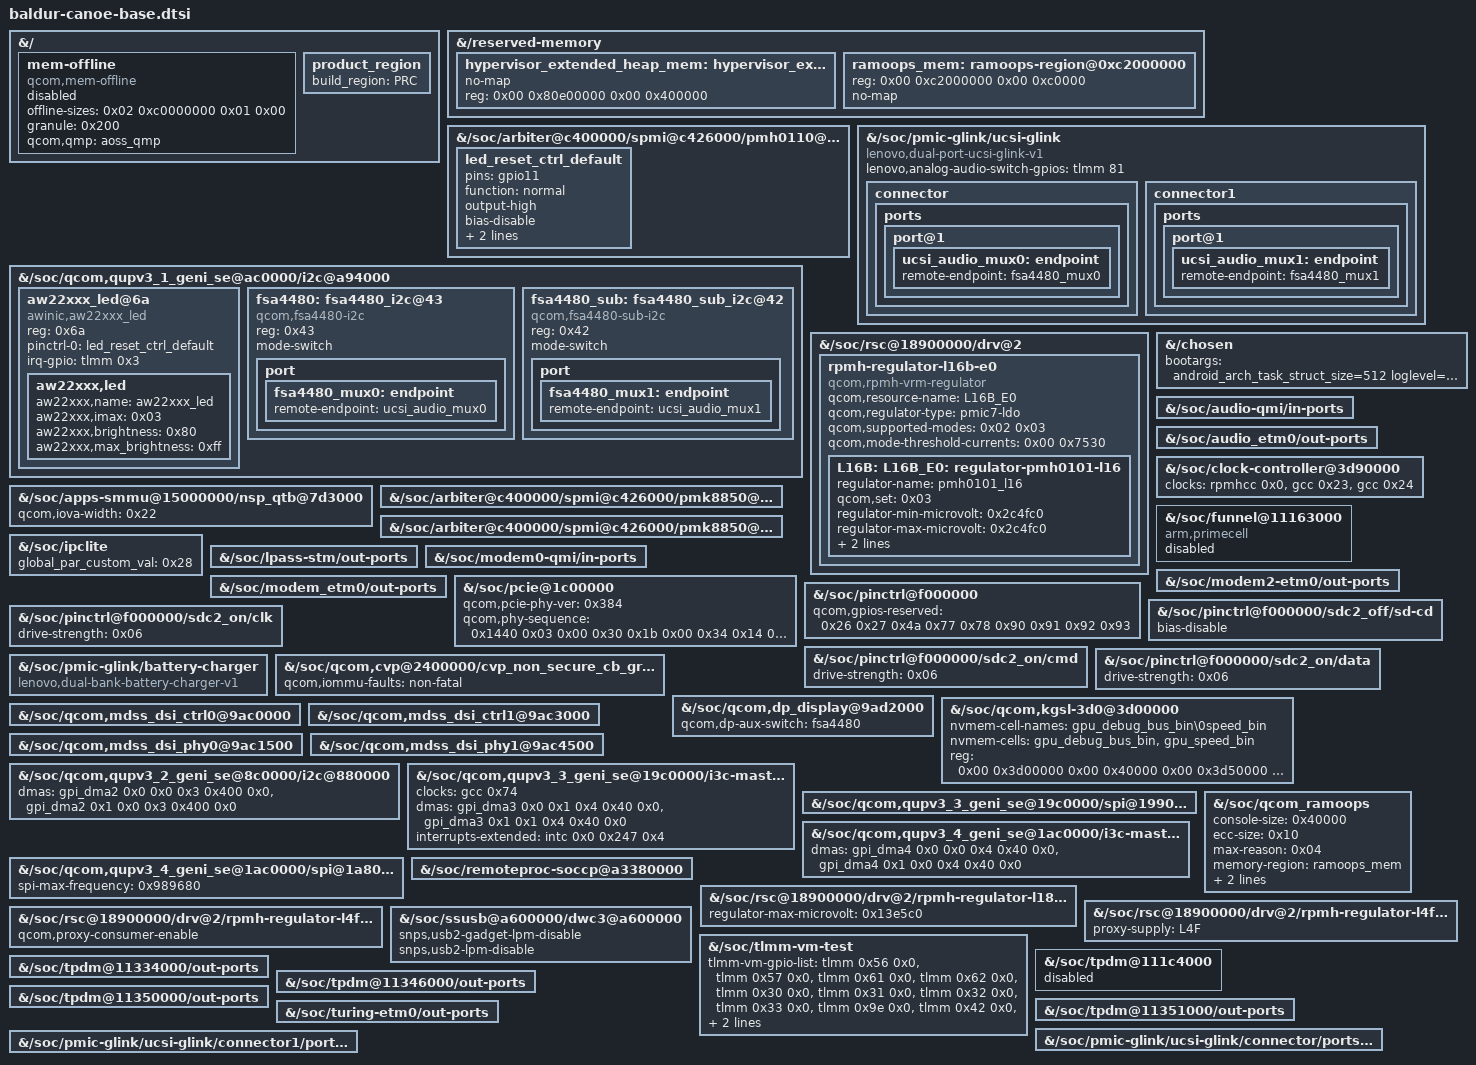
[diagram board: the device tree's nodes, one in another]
// SPDX-License-Identifier: GPL-2.0-only
// ZUXOS 2.0.12.088 PRC base entry 12 delta over the QTI CanoeP v2 techpack set.

/delete-node/ &{/ddr-regions};
/delete-node/ &{/reserved-memory/hypervisor_extended_heap_region@0xc3dd0000};
/delete-node/ &{/reserved-memory/ramoops-region};
/delete-node/ &{/reserved-memory/reserved_region@80e00000};
/delete-node/ &{/soc/arbiter@c400000/spmi@c426000/pmh0110@8/pinctrl@8800/cam-sensor-1p8-rst1-active-state};
/delete-node/ &{/soc/arbiter@c400000/spmi@c426000/pmh0110@8/pinctrl@8800/cam-sensor-1p8-rst1-suspend-state};
/delete-node/ &{/soc/arbiter@c400000/spmi@c426000/pmk8850@0/pinctrl@b800/alt-sleep-clk-default-state};
/delete-node/ &{/soc/arbiter@c400000/spmi@c426000/pmk8850@0/pinctrl@b800/xoagg-therm-default-state};
/delete-node/ &{/soc/arbiter@c400000/spmi@c426000/pmk8850@0/vadc@9000/pmh0101_cam_flash_therm};
/delete-node/ &{/soc/arbiter@c400000/spmi@c426000/pmk8850@0/vadc@9000/pmh0101_pa_therm1};
/delete-node/ &{/soc/arbiter@c400000/spmi@c426000/pmk8850@0/vadc@9000/pmh0101_pa_therm2};
/delete-node/ &{/soc/arbiter@c400000/spmi@c426000/pmk8850@0/vadc@9000/pmh0101_skin_therm};
/delete-node/ &{/soc/arbiter@c400000/spmi@c426000/pmk8850@0/vadc@9000/pmh0101_wlan_therm};
/delete-node/ &{/soc/arbiter@c400000/spmi@c426000/pmk8850@0/vadc@9000/pmk8850_xoagg_therm};
/delete-node/ &{/soc/funnel@11163000/in-ports};
/delete-node/ &{/soc/qcom,gpu-coresight-cx};
/delete-node/ &{/soc/qcom,gpu-coresight-gx};
/delete-node/ &{/soc/qcom,mdss_dsi_ctrl0@9ac0000/qcom,ctrl-supply-entries/qcom,ctrl-supply-entry@1};
/delete-node/ &{/soc/qcom,mdss_dsi_ctrl1@9ac3000/qcom,ctrl-supply-entries/qcom,ctrl-supply-entry@1};
/delete-node/ &{/soc/qcom,mdss_dsi_phy0@9ac1500/qcom,phy-supply-entries/qcom,phy-supply-entry@1};
/delete-node/ &{/soc/qcom,mdss_dsi_phy1@9ac4500/qcom,phy-supply-entries/qcom,phy-supply-entry@1};
/delete-node/ &{/soc/qfprom@221c8000/debugbus_en@783};
/delete-node/ &{/soc/qfprom@221c8000/gpu_niden_en@783};
/delete-node/ &{/soc/qmi-tmd-devices/modem/modem_bcl_mtpl_dsc};

&{/} {
	mem-offline {
		compatible = "qcom,mem-offline";
		status = "disabled";
		offline-sizes = <0x02 0xc0000000 0x01 0x00>;
		granule = <0x200>;
		qcom,qmp = <&aoss_qmp>;
	};
};

&{/} {
	product_region: product_region {
		build_region = "PRC";
	};
};

&{/reserved-memory} {
	hypervisor_extended_heap_mem: hypervisor_extended_heap_region@80e00000 {
		no-map;
		reg = <0x00 0x80e00000 0x00 0x400000>;
	};
};

&{/reserved-memory} {
	ramoops_mem: ramoops-region@0xc2000000 {
		reg = <0x00 0xc2000000 0x00 0xc0000>;
		no-map;
	};
};

&{/soc/arbiter@c400000/spmi@c426000/pmh0110@3/pinctrl@8800} {
	led_reset_ctrl_default: led_reset_ctrl_default {
		pins = "gpio11";
		function = "normal";
		output-high;
		bias-disable;
		power-source = <0x01>;
		qcom,drive-strength = <0x02>;
	};
};

&{/soc/pmic-glink/ucsi-glink} {
	compatible = "lenovo,dual-port-ucsi-glink-v1", "qcom,ucsi-glink";
	lenovo,analog-audio-switch-gpios = <&tlmm 81 GPIO_ACTIVE_HIGH>;
	connector {
		ports {
			port@1 {
				ucsi_audio_mux0: endpoint {
					remote-endpoint = <&fsa4480_mux0>;
				};
			};
		};
	};
};

&{/soc/pmic-glink/ucsi-glink} {
	connector1 {
		ports {
			port@1 {
				ucsi_audio_mux1: endpoint {
					remote-endpoint = <&fsa4480_mux1>;
				};
			};
		};
	};
};

&{/soc/qcom,qupv3_1_geni_se@ac0000/i2c@a94000} {
	aw22xxx_led@6a {
		compatible = "awinic,aw22xxx_led";
		reg = <0x6a>;
		pinctrl-names = "led_reset_ctrl_default";
		pinctrl-0 = <&led_reset_ctrl_default>;
		irq-gpio = <&tlmm 0x3 0x0>;
		status = "okay";
		aw22xxx,led {
			aw22xxx,name = "aw22xxx_led";
			aw22xxx,imax = <0x03>;
			aw22xxx,brightness = <0x80>;
			aw22xxx,max_brightness = <0xff>;
		};
	};
};

&{/soc/qcom,qupv3_1_geni_se@ac0000/i2c@a94000} {
	fsa4480: fsa4480_i2c@43 {
		compatible = "qcom,fsa4480-i2c";
		reg = <0x43>;
		mode-switch;
		port {
			fsa4480_mux0: endpoint {
				remote-endpoint = <&ucsi_audio_mux0>;
			};
		};
	};
};

&{/soc/qcom,qupv3_1_geni_se@ac0000/i2c@a94000} {
	fsa4480_sub: fsa4480_sub_i2c@42 {
		compatible = "qcom,fsa4480-sub-i2c";
		reg = <0x42>;
		mode-switch;
		port {
			fsa4480_mux1: endpoint {
				remote-endpoint = <&ucsi_audio_mux1>;
			};
		};
	};
};

&{/soc/rsc@18900000/drv@2} {
	rpmh-regulator-l16b-e0 {
		compatible = "qcom,rpmh-vrm-regulator";
		qcom,resource-name = "L16B_E0";
		qcom,regulator-type = "pmic7-ldo";
		qcom,supported-modes = <0x02 0x03>;
		qcom,mode-threshold-currents = <0x00 0x7530>;
		L16B: L16B_E0: pmh0101_l16: regulator-pmh0101-l16 {
			regulator-name = "pmh0101_l16";
			qcom,set = <0x03>;
			regulator-min-microvolt = <0x2c4fc0>;
			regulator-max-microvolt = <0x2c4fc0>;
			qcom,init-voltage = <0x2c4fc0>;
			qcom,init-mode = <0x03>;
		};
	};
};

&{/chosen} {
	bootargs = "android_arch_task_struct_size=512 loglevel=6 log_buf_len=512K cpufreq.default_governor=performance sysctl.kernel.sched_pelt_multiplier=4 no-steal-acc kpti=0 swiotlb=0 loop.max_part=7 irqaffinity=0-1 fw_devlink.strict=1 pcie_ports=compat pci-msm-drv.pcie_sm_regs=0x1D07000,0x1040,0x1048,0x3000,0x1 kasan=off rcupdate.rcu_expedited=1 rcu_nocbs=0-7 cgroup_disable=pressure printk.console_no_auto_verbose=1 sysctl.kernel.panic_on_rcu_stall=1 ftrace_dump_on_oops disable_dma32=on restrict_cma_redirect=false";
};

&{/soc/apps-smmu@15000000/nsp_qtb@7d3000} {
	qcom,iova-width = <0x22>;
};

&{/soc/arbiter@c400000/spmi@c426000/pmk8850@0/pinctrl@b800} {
	/delete-property/ pinctrl-0;
	/delete-property/ pinctrl-names;
};

&{/soc/arbiter@c400000/spmi@c426000/pmk8850@0/vadc@9000/pmh0101_qtm_therm} {
	/delete-property/ status;
};

&{/soc/audio-qmi/in-ports} {
	/delete-property/ #address-cells;
	/delete-property/ #size-cells;
};

&{/soc/audio_etm0/out-ports} {
	/delete-property/ #address-cells;
	/delete-property/ #size-cells;
};

&{/soc/clock-controller@3d90000} {
	clock-names = "bi_tcxo\0gpll0_out_main\0gpll0_out_main_div";
	clocks = <&rpmhcc 0x0 &gcc 0x23 &gcc 0x24>;
};

&{/soc/funnel@11163000} {
	compatible = "arm,primecell";
	status = "disabled";
};

&{/soc/ipclite} {
	global_par_custom_val = <0x28>;
};

&{/soc/lpass-stm/out-ports} {
	/delete-property/ #address-cells;
	/delete-property/ #size-cells;
};

&{/soc/modem0-qmi/in-ports} {
	/delete-property/ #address-cells;
	/delete-property/ #size-cells;
};

&{/soc/modem2-etm0/out-ports} {
	/delete-property/ #address-cells;
	/delete-property/ #size-cells;
};

&{/soc/modem_etm0/out-ports} {
	/delete-property/ #address-cells;
	/delete-property/ #size-cells;
};

&{/soc/pcie@1c00000} {
	qcom,pcie-phy-ver = <0x384>;
	qcom,phy-sequence = <0x1440 0x03 0x00 0x30 0x1b 0x00 0x34 0x14 0x00 0x7c 0x00 0x00 0x80 0x40 0x00 0x84 0x00 0x00 0xb4 0x04 0x00 0xe0 0x05 0x00 0xe4 0x00 0x00 0xf4 0x07 0x00 0xf8 0x1f 0x00 0x58 0x90 0x00 0x118 0x02 0x00 0x11c 0x0d 0x00 0x148 0x53 0x00 0x14c 0x54 0x00 0x2dc 0x0b 0x00 0x2ec 0x04 0x00 0x2f0 0x05 0x00 0x2f4 0x15 0x00 0x370 0x00 0x00 0x378 0x89 0x00 0x3b4 0x2d 0x00 0x128 0x20 0x00 0x3d8 0x1c 0x00 0x3e0 0x04 0x00 0x2b8 0x01 0x00 0x2bc 0x05 0x00 0x2c4 0x00 0x00 0x2c8 0x00 0x00 0x2b4 0x00 0x00 0x258 0x40 0x00 0x25c 0x42 0x00 0x284 0x18 0x00 0x298 0x12 0x00 0x2ac 0x18 0x00 0x418 0xc2 0x00 0x41c 0xc2 0x00 0x420 0x18 0x00 0x428 0x0f 0x00 0x434 0x62 0x00 0x460 0xe4 0x00 0x464 0x63 0x00 0x468 0xd8 0x00 0x46c 0x99 0x00 0x470 0x67 0x00 0x484 0xa4 0x00 0x488 0xa4 0x00 0x48c 0x28 0x00 0x490 0x9f 0x00 0x494 0x48 0x00 0x498 0x24 0x00 0x51c 0x01 0x00 0x520 0x00 0x00 0x31c 0xff 0x00 0x320 0xff 0x00 0x308 0x30 0x00 0x30c 0x03 0x00 0x398 0x1f 0x00 0x39c 0x1f 0x00 0x3a0 0x0d 0x00 0x830 0x1b 0x00 0x834 0x14 0x00 0x87c 0x00 0x00 0x880 0x40 0x00 0x884 0x00 0x00 0x8b4 0x04 0x00 0x8e0 0x05 0x00 0x8e4 0x00 0x00 0x8f4 0x07 0x00 0x8f8 0x1f 0x00 0x858 0x90 0x00 0x918 0x02 0x00 0x91c 0x0d 0x00 0x948 0x53 0x00 0x94c 0x54 0x00 0xadc 0x0b 0x00 0xaec 0x04 0x00 0xaf0 0x05 0x00 0xaf4 0x15 0x00 0xb70 0x00 0x00 0xb78 0x89 0x00 0xbb4 0x2d 0x00 0x928 0x20 0x00 0xbd8 0x1c 0x00 0xbe0 0x04 0x00 0xab8 0x01 0x00 0xabc 0x05 0x00 0xac4 0x00 0x00 0xac8 0x00 0x00 0xab4 0x00 0x00 0xa58 0x40 0x00 0xa5c 0x42 0x00 0xa84 0x18 0x00 0xa98 0x12 0x00 0xaac 0x18 0x00 0xc18 0xc2 0x00 0xc1c 0xc2 0x00 0xc20 0x18 0x00 0xc28 0x0f 0x00 0xc34 0x62 0x00 0xc60 0xe4 0x00 0xc64 0x63 0x00 0xc68 0xd8 0x00 0xc6c 0x99 0x00 0xc70 0x67 0x00 0xc84 0xa4 0x00 0xc88 0xa4 0x00 0xc8c 0x28 0x00 0xc90 0x9f 0x00 0xc94 0x48 0x00 0xc98 0x24 0x00 0xd1c 0x01 0x00 0xd20 0x00 0x00 0xb1c 0xff 0x00 0xb20 0xff 0x00 0xb08 0x30 0x00 0xb0c 0x03 0x00 0xb98 0x1f 0x00 0xb9c 0x1f 0x00 0xba0 0x0d 0x00 0x1000 0x93 0x00 0x1004 0x01 0x00 0x1010 0x06 0x00 0x1014 0x16 0x00 0x1018 0x36 0x00 0x101c 0x04 0x00 0x1020 0x0a 0x00 0x1024 0x1a 0x00 0x1028 0x34 0x00 0x1030 0x55 0x00 0x1034 0x55 0x00 0x1038 0x01 0x00 0x103c 0x01 0x00 0x1060 0xf8 0x00 0x1064 0x01 0x00 0x1070 0x06 0x00 0x1074 0x16 0x00 0x1078 0x36 0x00 0x107c 0x0a 0x00 0x1080 0x04 0x00 0x1084 0x0d 0x00 0x1088 0x41 0x00 0x1090 0xab 0x00 0x1094 0xaa 0x00 0x1098 0x01 0x00 0x109c 0x00 0x00 0x10bc 0x0a 0x00 0x10c0 0x01 0x00 0x10cc 0x62 0x00 0x10d0 0x02 0x00 0x10dc 0x14 0x00 0x10e0 0x90 0x00 0x10e4 0x82 0x00 0x10f4 0x0f 0x00 0x1110 0x08 0x00 0x1120 0x46 0x00 0x1124 0x04 0x00 0x1140 0x14 0x00 0x1164 0x34 0x00 0x1170 0xa0 0x00 0x1174 0x16 0x00 0x1184 0x88 0x00 0x1188 0x04 0x00 0x1198 0x0f 0x00 0x12b4 0x02 0x00 0x1570 0x17 0x00 0x1578 0x2e 0x00 0x1590 0xcc 0x00 0x15b8 0x40 0x00 0x15dc 0x04 0x00 0x15e0 0x02 0x00 0x1818 0xc0 0x00 0x15f8 0x00 0x00 0x15fc 0x22 0x00 0x180c 0x1d 0x00 0x181c 0xc1 0x00 0x1890 0x00 0x00 0x18a0 0x16 0x00 0x18f0 0x27 0x00 0x18f4 0x27 0x00 0x1908 0x02 0x00 0x195c 0x2e 0x00 0x197c 0x03 0x00 0x1984 0x28 0x00 0x198c 0x0f 0x00 0x19ac 0xf2 0x00 0x19c0 0xf2 0x00 0x19d0 0x1f 0x00 0x1400 0x00 0x00 0x1444 0x03 0x00>;
};

&{/soc/pinctrl@f000000} {
	qcom,gpios-reserved = <0x26 0x27 0x4a 0x77 0x78 0x90 0x91 0x92 0x93>;
};

&{/soc/pinctrl@f000000/sdc2_off/sd-cd} {
	bias-disable;
	/delete-property/ bias-pull-up;
};

&{/soc/pinctrl@f000000/sdc2_on/clk} {
	drive-strength = <0x06>;
};

&{/soc/pinctrl@f000000/sdc2_on/cmd} {
	drive-strength = <0x06>;
};

&{/soc/pinctrl@f000000/sdc2_on/data} {
	drive-strength = <0x06>;
};

&{/soc/pmic-glink/battery-charger} {
	compatible = "lenovo,dual-bank-battery-charger-v1", "qcom,battery-charger";
};

&{/soc/qcom,cvp@2400000/cvp_non_secure_cb_group} {
	qcom,iommu-faults = "non-fatal";
};

&{/soc/qcom,dp_display@9ad2000} {
	qcom,dp-aux-switch = <&fsa4480>;
};

&{/soc/qcom,kgsl-3d0@3d00000} {
	nvmem-cell-names = "gpu_debug_bus_bin\0speed_bin";
	nvmem-cells = <&gpu_debug_bus_bin &gpu_speed_bin>;
	/delete-property/ qcom,gpu-qdss-stm;
	reg = <0x00 0x3d00000 0x00 0x40000 0x00 0x3d50000 0x00 0x10000 0x00 0x3d61000 0x00 0x3000 0x00 0x3d9e000 0x00 0x2000 0x00 0x11100000 0x00 0x80000>;
	reg-names = "kgsl_3d0_reg_memory\0rscc\0cx_dbgc\0cx_misc\0qdss_gfx";
};

&{/soc/qcom,mdss_dsi_ctrl0@9ac0000} {
	/delete-property/ vdda-1p2-parent-supply;
};

&{/soc/qcom,mdss_dsi_ctrl1@9ac3000} {
	/delete-property/ vdda-1p2-parent-supply;
};

&{/soc/qcom,mdss_dsi_phy0@9ac1500} {
	/delete-property/ vdda-0p9-parent-supply;
};

&{/soc/qcom,mdss_dsi_phy1@9ac4500} {
	/delete-property/ vdda-0p9-parent-supply;
};

&{/soc/qcom,qupv3_1_geni_se@ac0000/i2c@a94000} {
	status = "okay";
};

&{/soc/qcom,qupv3_2_geni_se@8c0000/i2c@880000} {
	dmas = <&gpi_dma2 0x0 0x0 0x3 0x400 0x0 &gpi_dma2 0x1 0x0 0x3 0x400 0x0>;
};

&{/soc/qcom,qupv3_3_geni_se@19c0000/i3c-master@1984000} {
	clock-names = "se-clk";
	clocks = <&gcc 0x74>;
	dmas = <&gpi_dma3 0x0 0x1 0x4 0x40 0x0 &gpi_dma3 0x1 0x1 0x4 0x40 0x0>;
	/delete-property/ interrupts;
	interrupts-extended = <&intc 0x0 0x247 0x4>;
};

&{/soc/qcom,qupv3_3_geni_se@19c0000/spi@1990000} {
	/delete-property/ qcom,ipc-size;
};

&{/soc/qcom,qupv3_4_geni_se@1ac0000/i3c-master@1a80000} {
	dmas = <&gpi_dma4 0x0 0x0 0x4 0x40 0x0 &gpi_dma4 0x1 0x0 0x4 0x40 0x0>;
};

&{/soc/qcom,qupv3_4_geni_se@1ac0000/spi@1a80000} {
	spi-max-frequency = <0x989680>;
};

&{/soc/qcom_ramoops} {
	console-size = <0x40000>;
	ecc-size = <0x10>;
	max-reason = <0x04>;
	memory-region = <&ramoops_mem>;
	pmsg-size = <0x40000>;
	record-size = <0x10000>;
};

&{/soc/remoteproc-soccp@a3380000} {
	/delete-property/ interconnect-names;
	/delete-property/ interconnects;
};

&{/soc/rsc@18900000/drv@2/rpmh-regulator-l18b-e0/regulator-pmh0101-l18} {
	regulator-max-microvolt = <0x13e5c0>;
};

&{/soc/rsc@18900000/drv@2/rpmh-regulator-l4f-e0} {
	proxy-supply = <&L4F>;
};

&{/soc/rsc@18900000/drv@2/rpmh-regulator-l4f-e0/regulator-pmh0110-f-l4} {
	qcom,proxy-consumer-enable;
};

&{/soc/ssusb@a600000/dwc3@a600000} {
	snps,usb2-gadget-lpm-disable;
	snps,usb2-lpm-disable;
};

&{/soc/tlmm-vm-test} {
	tlmm-vm-gpio-list = <&tlmm 0x56 0x0 &tlmm 0x57 0x0 &tlmm 0x61 0x0 &tlmm 0x62 0x0 &tlmm 0x30 0x0 &tlmm 0x31 0x0 &tlmm 0x32 0x0 &tlmm 0x33 0x0 &tlmm 0x9e 0x0 &tlmm 0x42 0x0 &tlmm 0x64 0x0 &tlmm 0x8 0x0 &tlmm 0x9 0x0 &tlmm 0xa 0x0 &tlmm 0xb 0x0 &tlmm 0x58 0x0>;
};

&{/soc/tpdm@111c4000} {
	status = "disabled";
};

&{/soc/tpdm@11334000/out-ports} {
	/delete-property/ #address-cells;
	/delete-property/ #size-cells;
};

&{/soc/tpdm@11346000/out-ports} {
	/delete-property/ #address-cells;
	/delete-property/ #size-cells;
};

&{/soc/tpdm@11350000/out-ports} {
	/delete-property/ #address-cells;
	/delete-property/ #size-cells;
};

&{/soc/tpdm@11351000/out-ports} {
	/delete-property/ #address-cells;
	/delete-property/ #size-cells;
};

&{/soc/turing-etm0/out-ports} {
	/delete-property/ #address-cells;
	/delete-property/ #size-cells;
};

// The current DTBO replaces these endpoint handles without rewriting all
// inherited references. Preserve the stock stale values for merged equivalence.
&{/soc/pmic-glink/ucsi-glink/connector/ports/port@1/endpoint} { phandle = <0x2cc>; };
&{/soc/pmic-glink/ucsi-glink/connector1/ports/port@1/endpoint} { phandle = <0x2cb>; };
